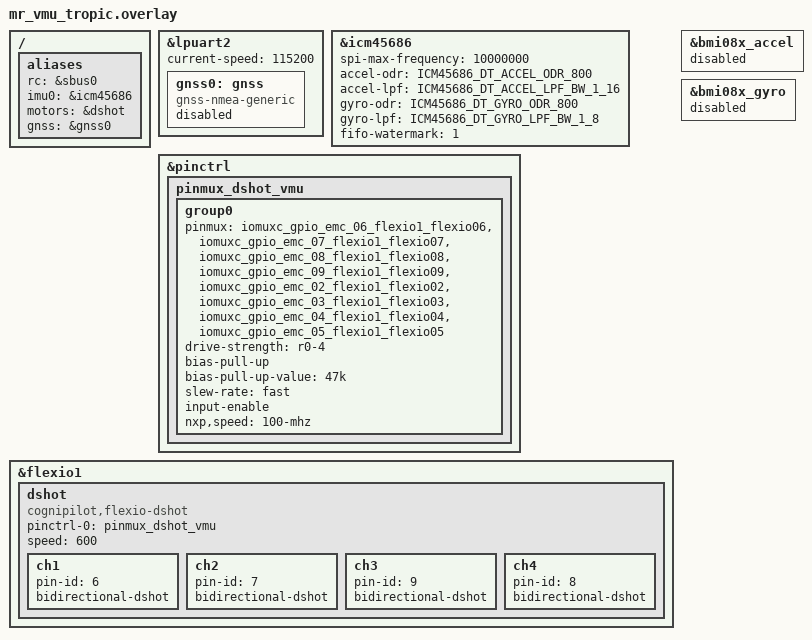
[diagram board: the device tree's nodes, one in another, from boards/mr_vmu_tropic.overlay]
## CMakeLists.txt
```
cmake_minimum_required(VERSION 3.20.0)

list(APPEND DTS_ROOT ${CMAKE_CURRENT_SOURCE_DIR})

get_filename_component(WORKSPACE_ROOT ${CMAKE_CURRENT_SOURCE_DIR} DIRECTORY)
set(ZEPHYR_MODULES
  ${WORKSPACE_ROOT}/modules/hal/cmsis_6
  ${WORKSPACE_ROOT}/modules/hal/nxp
  ${WORKSPACE_ROOT}/modules/lib/zephyr_boards
)

find_package(Zephyr REQUIRED HINTS $ENV{ZEPHYR_BASE})
project(cerebri2 LANGUAGES C)

set(CEREBRI2_FLATBUFFER_SCHEMA_DIR
  ${WORKSPACE_ROOT}/modules/lib/synapse_msgs_fbs/fbs/cerebri2
)
set(CEREBRI2_FLATBUFFER_SCHEMA
  ${CEREBRI2_FLATBUFFER_SCHEMA_DIR}/cerebri2_topics.fbs
)
set(CEREBRI2_FLATBUFFER_LOG_SCHEMA
  ${CEREBRI2_FLATBUFFER_SCHEMA_DIR}/cerebri2_log.fbs
)
set(CEREBRI2_FLATBUFFER_SIL_SCHEMA
  ${CEREBRI2_FLATBUFFER_SCHEMA_DIR}/cerebri2_sil.fbs
)
set(CEREBRI2_FLATBUFFER_GENERATED_DIR
  ${CMAKE_CURRENT_BINARY_DIR}/generated/flatbuffers
)
set(CEREBRI2_FLATBUFFER_STAMP
  ${CEREBRI2_FLATBUFFER_GENERATED_DIR}/.flatcc.stamp
)
set(CEREBRI2_FLATBUFFER_BFBS_STAMP
  ${CEREBRI2_FLATBUFFER_GENERATED_DIR}/.bfbs.stamp
)
set(CEREBRI2_FLATBUFFER_STAGE_STAMP
  ${CEREBRI2_FLATBUFFER_GENERATED_DIR}/.schema-copy.stamp
)
option(CEREBRI2_FLATBUFFER_CODEGEN
  "Generate FlatBuffer C headers and binary schemas into the build tree when flatcc is available"
  ON
)

find_program(CEREBRI2_FLATCC_EXECUTABLE NAMES flatcc)

if(NOT EXISTS ${CEREBRI2_FLATBUFFER_SCHEMA})
  message(FATAL_ERROR
    "Missing FlatBuffer topic schema: ${CEREBRI2_FLATBUFFER_SCHEMA}. "
    "Run west update to fetch modules/lib/synapse_msgs_fbs."
  )
endif()

if(NOT EXISTS ${CEREBRI2_FLATBUFFER_LOG_SCHEMA})
  message(FATAL_ERROR
    "Missing FlatBuffer log schema: ${CEREBRI2_FLATBUFFER_LOG_SCHEMA}. "
    "Run west update to fetch modules/lib/synapse_msgs_fbs."
  )
endif()

if(NOT EXISTS ${CEREBRI2_FLATBUFFER_SIL_SCHEMA})
  message(FATAL_ERROR
    "Missing FlatBuffer SITL schema: ${CEREBRI2_FLATBUFFER_SIL_SCHEMA}. "
    "Run west update to fetch modules/lib/synapse_msgs_fbs."
  )
endif()

if(CEREBRI2_FLATBUFFER_CODEGEN AND CEREBRI2_FLATCC_EXECUTABLE)
  add_custom_command(
    OUTPUT ${CEREBRI2_FLATBUFFER_STAGE_STAMP}
    COMMAND ${CMAKE_COMMAND} -E make_directory ${CEREBRI2_FLATBUFFER_GENERATED_DIR}
    COMMAND ${CMAKE_COMMAND} -E copy_if_different
            ${CEREBRI2_FLATBUFFER_SCHEMA}
            ${CEREBRI2_FLATBUFFER_GENERATED_DIR}/cerebri2_topics.fbs
    COMMAND ${CMAKE_COMMAND} -E copy_if_different
            ${CEREBRI2_FLATBUFFER_LOG_SCHEMA}
            ${CEREBRI2_FLATBUFFER_GENERATED_DIR}/cerebri2_log.fbs
    COMMAND ${CMAKE_COMMAND} -E copy_if_different
            ${CEREBRI2_FLATBUFFER_SIL_SCHEMA}
            ${CEREBRI2_FLATBUFFER_GENERATED_DIR}/cerebri2_sil.fbs
    COMMAND ${CMAKE_COMMAND} -E touch ${CEREBRI2_FLATBUFFER_STAGE_STAMP}
    DEPENDS
      ${CEREBRI2_FLATBUFFER_SCHEMA}
      ${CEREBRI2_FLATBUFFER_LOG_SCHEMA}
      ${CEREBRI2_FLATBUFFER_SIL_SCHEMA}
    COMMENT "Staging FlatBuffer schemas into ${CEREBRI2_FLATBUFFER_GENERATED_DIR}"
    VERBATIM
  )

  add_custom_command(
    OUTPUT ${CEREBRI2_FLATBUFFER_STAMP}
    COMMAND ${CEREBRI2_FLATCC_EXECUTABLE}
            -a
            -I${CEREBRI2_FLATBUFFER_SCHEMA_DIR}
            -o${CEREBRI2_FLATBUFFER_GENERATED_DIR}
            ${CEREBRI2_FLATBUFFER_SCHEMA}
    COMMAND ${CEREBRI2_FLATCC_EXECUTABLE}
            -a
            -I${CEREBRI2_FLATBUFFER_SCHEMA_DIR}
            -o${CEREBRI2_FLATBUFFER_GENERATED_DIR}
            ${CEREBRI2_FLATBUFFER_LOG_SCHEMA}
    COMMAND ${CEREBRI2_FLATCC_EXECUTABLE}
            -a
            -I${CEREBRI2_FLATBUFFER_SCHEMA_DIR}
            -o${CEREBRI2_FLATBUFFER_GENERATED_DIR}
            ${CEREBRI2_FLATBUFFER_SIL_SCHEMA}
    COMMAND ${CMAKE_COMMAND} -E touch ${CEREBRI2_FLATBUFFER_STAMP}
    DEPENDS
      ${CEREBRI2_FLATBUFFER_STAGE_STAMP}
      ${CEREBRI2_FLATBUFFER_SCHEMA}
      ${CEREBRI2_FLATBUFFER_LOG_SCHEMA}
      ${CEREBRI2_FLATBUFFER_SIL_SCHEMA}
    COMMENT "Generating FlatBuffer headers into ${CEREBRI2_FLATBUFFER_GENERATED_DIR}"
    VERBATIM
  )

  add_custom_target(cerebri2_flatbuffer_codegen DEPENDS ${CEREBRI2_FLATBUFFER_STAMP})
  add_custom_command(
    OUTPUT ${CEREBRI2_FLATBUFFER_BFBS_STAMP}
    COMMAND ${CMAKE_COMMAND} -E make_directory ${CEREBRI2_FLATBUFFER_GENERATED_DIR}
    COMMAND ${CMAKE_COMMAND} -E copy_if_different
            ${CEREBRI2_FLATBUFFER_SCHEMA}
            ${CEREBRI2_FLATBUFFER_GENERATED_DIR}/cerebri2_topics.fbs
    COMMAND ${CMAKE_COMMAND} -E copy_if_different
            ${CEREBRI2_FLATBUFFER_LOG_SCHEMA}
            ${CEREBRI2_FLATBUFFER_GENERATED_DIR}/cerebri2_log.fbs
    COMMAND ${CEREBRI2_FLATCC_EXECUTABLE}
            --schema
            -I${CEREBRI2_FLATBUFFER_SCHEMA_DIR}
            -o${CEREBRI2_FLATBUFFER_GENERATED_DIR}
            ${CEREBRI2_FLATBUFFER_SCHEMA}
    COMMAND ${CEREBRI2_FLATCC_EXECUTABLE}
            --schema
            -I${CEREBRI2_FLATBUFFER_SCHEMA_DIR}
            -o${CEREBRI2_FLATBUFFER_GENERATED_DIR}
            ${CEREBRI2_FLATBUFFER_LOG_SCHEMA}
    COMMAND ${CEREBRI2_FLATCC_EXECUTABLE}
            --schema
            -I${CEREBRI2_FLATBUFFER_SCHEMA_DIR}
            -o${CEREBRI2_FLATBUFFER_GENERATED_DIR}
            ${CEREBRI2_FLATBUFFER_SIL_SCHEMA}
    COMMAND ${CMAKE_COMMAND} -E touch ${CEREBRI2_FLATBUFFER_BFBS_STAMP}
    DEPENDS
      ${CEREBRI2_FLATBUFFER_STAGE_STAMP}
      ${CEREBRI2_FLATBUFFER_SCHEMA}
      ${CEREBRI2_FLATBUFFER_LOG_SCHEMA}
      ${CEREBRI2_FLATBUFFER_SIL_SCHEMA}
    COMMENT "Generating FlatBuffer binary schemas into ${CEREBRI2_FLATBUFFER_GENERATED_DIR}"
    VERBATIM
  )

  add_custom_target(cerebri2_flatbuffer_schema_codegen
    DEPENDS ${CEREBRI2_FLATBUFFER_BFBS_STAMP}
  )
elseif(CEREBRI2_FLATBUFFER_CODEGEN)
  message(STATUS
    "flatcc not found; skipping FlatBuffer code generation and using local topic codec only"
  )
endif()

target_sources(app PRIVATE
  src/main.c
  src/rc_input.c
  src/topic_flatbuffer.c
  src/topic_shell.c
  src/PIDAxis.c
  drivers/nxp_flexio_dshot.c
  drivers/nxp_flexio_dshot_api.c
  src/rdd2.c
)

if(CONFIG_CEREBRI2_DSHOT)
  target_sources(app PRIVATE drivers/nxp_flexio_dshot.c)
endif()

if(CONFIG_CEREBRI2_SITL)
  target_sources(app PRIVATE
    src/sitl_flatbuffer.c
    drivers/sitl_dshot.c
    drivers/sitl_imu.c
    drivers/sitl_rc.c
    drivers/sitl_udp_coordinator.c
  )
endif()

if(TARGET cerebri2_flatbuffer_codegen)
  add_dependencies(app cerebri2_flatbuffer_codegen)
endif()

if(TARGET cerebri2_flatbuffer_schema_codegen)
  add_dependencies(app cerebri2_flatbuffer_schema_codegen)
endif()

target_include_directories(app PRIVATE
  include
  src
  ${CEREBRI2_FLATBUFFER_GENERATED_DIR}
  ${ZEPHYR_BASE}/../modules/hal/nxp/mcux/mcux-sdk-ng/drivers/flexio
)

# Automatically takes modelica model and generates it into C code
# Will be uncommented once rumoca is updated with new embedded-c backend
# And updated

#[[
if(TARGET cerebri_flatbuffer_schema_codegen)
  add_dependencies(app cerebri2_flatbuffer_schema_codegen)
endif()

target_include_directories(app PRIVATE
  include
  src
  ${CEREBRI2_FLATBUFFER_GENERATED_DIR}
  ${ZEPHYR_BASE}/../modules/hal/nxp/mcux/mcux-sdk-ng/drivers/flexio
)

# RUMOCA CODE GENERATION
set(RUMOCA_PATH ${WORKSPACE_ROOT}/modules/lib/rumoca)
set(RUMOCA_GENERATED_DIR ${CMAKE_CURRENT_BINARY_DIR}/generated/rumoca)
set(RUMOCA_STAMP ${RUMOCA_GENERATED_DIR}/.rumoca.stamp)

option(CEREBRI2_RUMOCA_CODEGEN
  "Generate rumoca embedded C"
  ON
)

find_program(CEREBRI2_RUMOCA_EXECUTABLE NAMES rumoca)

if (CEREBRI2_RUMOCA_CODEGEN AND CEREBRI2_RUMOCA_EXECUTABLE AND EXISTS ${RUMOCA_PATH}/models/Adder.mo)
  add_custom_command(
    OUTPUT ${RUMOCA_STAMP}
    COMMAND ${CMAKE_COMMAND} -E make_directory ${RUMOCA_GENERATED_DIR}
    COMMAND ${CEREBRI2_RUMOCA_EXECUTABLE} compile -b embedded-c -m Adder ${RUMOCA_PATH}/models/Adder.mo > ${RUMOCA_GENERATED_DIR}/adder.h
    COMMAND ${CMAKE_COMMAND} -E touch ${RUMOCA_STAMP}
    DEPENDS ${RUMOCA_PATH}/models/Adder.mo
    COMMENT "Generating rumoca embedded C code into ${RUMOCA_GENERATED_DIR}"
    VERBATIM
  )

  add_custom_target(cerebri2_rumoca_codegen DEPENDS ${RUMOCA_STAMP})

  if(TARGET cerebri2_rumoca_codegen)
    add_dependencies(app cerebri2_rumoca_codegen)
  endif()

elseif(CEREBRI2_RUMOCA_CODEGEN)
  message(STATUS
    "rumoca not found or Adder.mo missing; skipping rumoca code generation"
  )
endif()

target_include_directories(app PRIVATE
  ${RUMOCA_GENERATED_DIR}
)
]]
```

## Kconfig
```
source "Kconfig.zephyr"

menu "cerebri"

rsource "subsys/Kconfig"
rsource "drivers/Kconfig"

endmenu
```

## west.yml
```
# Copyright (c) 2023 CogniPilot Foundation
# SPDX-License-Identifier: Apache-2.0

manifest:

  group-filter:
    - +optional

  self:
    west-commands: scripts/west-commands.yml

  remotes:
    - name: zephyrproject-rtos
      url-base: https://github.com/zephyrproject-rtos
    - name: cognipilot
      url-base: https://github.com/CogniPilot

  projects:
    - name: zephyr
      remote: cognipilot
      west-commands: scripts/west-commands.yml
      revision: fd02d713535e8e683ec0e34fb942a08fe955878d # main-with-patches 07/06/26
      import:
        - name-allowlist:
          - nanopb
          - mbedtls
          - hal_nxp
          - cmsis
          - cmsis-dsp
          - cmsis_6
          - fatfs
          - open-amp
          - libmetal
          - segger
    - name: zros
      remote: cognipilot
      revision: 843348bca3a15e914914b90057369b9616302e20 # main 10/27/25
      path: modules/lib/zros
    - name: cyecca
      remote: cognipilot
      revision: 64d1f0dc5127d85765909f0c3525cc38305dac19 # main 11/17/25
      path: modules/lib/cyecca
    - name: synapse_pb
      remote: cognipilot
      revision: f038dd178faac0481033e5e4c757e31777c1b0be # main 11/10/25
      path: modules/lib/synapse_pb
    - name: hal_nxp
      remote: cognipilot
      revision: cf8f1631e862528ee044850bcc70273975b90771 # master 10/27/25
      path: modules/hal/nxp
    - name: zros_drivers
      remote: cognipilot
      revision: 61dba155d8f5f8e82419ca8c8901a47dbd00b480 # main 01/07/26
      path: modules/lib/zros_drivers
    - name: zephyr_boards
      remote: cognipilot
      revision: 33ee8e3c572ca53ea048d3ea62cc0c5dcd0895d6 # main 07/06/26
      path: modules/lib/zephyr_boards
```

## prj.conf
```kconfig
CONFIG_MAIN_STACK_SIZE=6144
CONFIG_MAIN_THREAD_PRIORITY=2
CONFIG_SYSTEM_WORKQUEUE_STACK_SIZE=2048
CONFIG_THREAD_NAME=y

CONFIG_ASSERT=y
CONFIG_FPU=y

CONFIG_LOG=y
CONFIG_LOG_MODE_IMMEDIATE=y
CONFIG_LOG_DEFAULT_LEVEL=2
CONFIG_LOG_CMDS=y
CONFIG_LOG_BACKEND_UART=n
CONFIG_LOG_PRINTK=n

CONFIG_CONSOLE=y
CONFIG_SERIAL=y
CONFIG_UART_ASYNC_API=y
CONFIG_UART_INTERRUPT_DRIVEN=y

CONFIG_SHELL=y
CONFIG_SHELL_BACKEND_SERIAL=y
CONFIG_SHELL_LOG_BACKEND=y
CONFIG_SHELL_PROMPT_UART="cerebri2:~$ "
CONFIG_SHELL_STACK_SIZE=4096
CONFIG_DEVICE_SHELL=y
CONFIG_KERNEL_SHELL=y
```

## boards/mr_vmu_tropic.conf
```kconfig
CONFIG_INPUT=y
CONFIG_INPUT_MODE_SYNCHRONOUS=y
CONFIG_INPUT_SHELL=y
CONFIG_INPUT_EVENT_DUMP=y
CONFIG_INPUT_CRSF=y
CONFIG_INPUT_CRSF_SEND_SYNC=y
CONFIG_INPUT_CRSF_REPORT_FILTER=1
CONFIG_INPUT_CRSF_THREAD_PRIORITY=1
CONFIG_INPUT_CRSF_THREAD_STACK_SIZE=2048
CONFIG_INPUT_CRSF_USE_DTCM_FOR_DMA_BUFFER=y

CONFIG_SENSOR=y
CONFIG_SENSOR_SHELL=y
CONFIG_ICM45686_STREAM=y
CONFIG_PINCTRL=y
CONFIG_CLOCK_CONTROL=y
CONFIG_DMA=y
CONFIG_SPI_NXP_LPSPI_DMA=n
CONFIG_GNSS=y
```

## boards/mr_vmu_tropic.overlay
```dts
/* SPDX-License-Identifier: Apache-2.0 */

#include <zephyr/dt-bindings/sensor/icm45686.h>

/ {
	aliases {
		rc = &sbus0;
		imu0 = &icm45686;
		motors = &dshot;
		gnss = &gnss0;
	};
};

&lpuart2 {
	status = "okay";
	current-speed = <115200>;

	gnss0: gnss {
		status = "disabled";
		compatible = "gnss-nmea-generic";
	};
};

&icm45686 {
	spi-max-frequency = <10000000>;
	/*
	 * Pace the flight loop directly from the IMU FIFO watermark at 800 Hz.
	 * Keep the filter settings conservative enough to cut motor vibration,
	 * but leave the SPI DMA channels intact so the FIFO read can stay off
	 * the CPU hot path.
	 */
	accel-odr = <ICM45686_DT_ACCEL_ODR_800>;
	accel-lpf = <ICM45686_DT_ACCEL_LPF_BW_1_16>;
	gyro-odr = <ICM45686_DT_GYRO_ODR_800>;
	gyro-lpf = <ICM45686_DT_GYRO_LPF_BW_1_8>;
	fifo-watermark = <1>;
};

&pinctrl {
	pinmux_dshot_vmu: pinmux_dshot_vmu {
		group0 {
			pinmux = <&iomuxc_gpio_emc_06_flexio1_flexio06>,
				 <&iomuxc_gpio_emc_07_flexio1_flexio07>,
				 <&iomuxc_gpio_emc_08_flexio1_flexio08>,
				 <&iomuxc_gpio_emc_09_flexio1_flexio09>,
				 <&iomuxc_gpio_emc_02_flexio1_flexio02>,
				 <&iomuxc_gpio_emc_03_flexio1_flexio03>,
				 <&iomuxc_gpio_emc_04_flexio1_flexio04>,
				 <&iomuxc_gpio_emc_05_flexio1_flexio05>;
			drive-strength = "r0-4";
			bias-pull-up;
			bias-pull-up-value = "47k";
			slew-rate = "fast";
			input-enable;
			nxp,speed = "100-mhz";
		};
	};
};

&flexio1 {
	status = "okay";

	dshot: dshot {
		compatible = "cognipilot,flexio-dshot";
		pinctrl-0 = <&pinmux_dshot_vmu>;
		pinctrl-names = "default";
		status = "okay";
		speed = <600>;

		ch1 {
			pin-id = <6>;
			bidirectional-dshot;
		};

		ch2 {
			pin-id = <7>;
			bidirectional-dshot;
		};

		ch3 {
			pin-id = <9>;
			bidirectional-dshot;
		};

		ch4 {
			pin-id = <8>;
			bidirectional-dshot;
		};
	};
};

&bmi08x_accel {
	status = "disabled";
};

&bmi08x_gyro {
	status = "disabled";
};
```

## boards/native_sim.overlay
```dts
/* SPDX-License-Identifier: Apache-2.0 */

/ {
	aliases {
		rc = &sitl_rc0;
		imu0 = &sitl_imu0;
		motors = &sitl_dshot0;
	};

	sitl_rc0: sitl_rc {
		compatible = "cognipilot,sitl-rc";
		status = "okay";
	};

	sitl_imu0: sitl_imu {
		compatible = "cognipilot,sitl-imu";
		status = "okay";
	};

	sitl_dshot0: sitl_dshot {
		compatible = "cognipilot,sitl-dshot";
		status = "okay";
		channel-count = <4>;
	};
};
```

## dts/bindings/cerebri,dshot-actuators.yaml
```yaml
# Copyright CogniPilot Foundation 2024
# SPDX-License-Identifier: Apache-2.0

description: DSHOT actuators parent node

  A generic binding for DSHOT actuators. Note that this binding
  has no vendor prefix, as it does not target a specific device or vendor.

compatible: "cerebri,dshot-actuators"

properties:
  rate:
    type: int
    default: 200
    description: |
      Update rate of the dshot signal in Hz

  disarm-timeout-ms:
    type: int
    default: 20
    description: |
      Inactivity timeout to disarm the DShot actuators, which is: no actuator
      update is received within this time.

child-binding:
  description: DSHOT actuators node
  properties:
    label:
      type: string
      description : user label

    center:
      required: true
      type: int
      description: Center dshot defaults to signal in ms to send (maps 0 input to dshot)

    scale:
      required: true
      type: int
      description: The scale in dshot per unit of input

    scale-div:
      default: 1
      type: int
      description: A divisor for the scale

    input-index:
      required: true
      type: int
      description: Index of actuator field specified by actuator input-type.

    input-type:
      required: true
      type: string
      description: What type of input singal to actuators
      enum:
        - "normalized"
        - "velocity"
```

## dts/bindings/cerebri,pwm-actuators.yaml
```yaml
# Copyright CogniPilot Foundation 2024
# SPDX-License-Identifier: Apache-2.0

description: PWM actuators parent node

  A generic binding for PWM actuators. Note that this binding
  has no vendor prefix, as it does not target a specific device or vendor.

compatible: "cerebri,pwm-actuators"

child-binding:
  description: PWM actuators node
  properties:
    label:
      type: string
      description : user label

    pwms:
      required: true
      type: phandle-array
      description: Reference to a PWM instance.

    disarmed:
      default: 1000
      type: int
      description: pwm defaults to signal in ms to send when disarmed

    min:
      default: 1100
      type: int
      description: Minimum pwm defaults to signal in ms to send

    center:
      required: true
      type: int
      description: Center pwm defaults to signal in ms to send (maps 0 input to pwm)

    scale:
      required: true
      type: int
      description: The scale in pwm per unit of input

    scale-div:
      default: 1
      type: int
      description: A divisor for the scale

    max:
      default: 1900
      type: int
      description: Maximum pwm defaults to signal in ms to send

    use-nano-seconds:
      type: boolean
      description: Use nanoseconds for pwm signal

    input-index:
      required: true
      type: int
      description: Index of actuator field specified by actuator input-type.

    input-type:
      required: true
      type: string
      description: What type of input singal to actuators
      enum:
        - "normalized"
        - "position"
        - "velocity"
```

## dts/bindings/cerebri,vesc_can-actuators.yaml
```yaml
# Copyright CogniPilot Foundation 2024
# SPDX-License-Identifier: Apache-2.0

description: VESC_CAN actuators parent node

  A generic binding for VESC_CAN actuators. Note that this binding
  has no vendor prefix, as it does not target a specific device or vendor.

compatible: "cerebri,vesc_can-actuators"

properties:
  device:
    required: true
    type: phandle
    description: Reference to a VESC_CAN instance.

  fd:
    type: boolean
    description: enable CAN FD mode

  pub-wheel-odometry:
    type: boolean
    description: Publishes wheel odometry on the average of all wheels

  status-rate:
    required: true
    type: int
    description: vesc can status publication rate in Hz. If status-rate <0> disables.

child-binding:
  description: VESC_CAN actuators node
  properties:

    vesc-id:
      required: true
      type: int
      description: vesc can bus id

    pole-pair:
      required: true
      type: int
      description: number of pole pairs

    input-index:
      required: true
      type: int
      description: Index of actuator field specified by actuator input-type.

    input-type:
      required: true
      type: string
      description: What type of input singal to actuators
      enum:
        - "normalized"
        - "position"
        - "velocity"
```

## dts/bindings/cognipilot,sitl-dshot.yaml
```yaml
# SPDX-License-Identifier: Apache-2.0

description: Cerebri native_sim DSHOT output device

compatible: "cognipilot,sitl-dshot"

include: sensor-device.yaml

properties:
  channel-count:
    type: int
    required: true
    description: Number of simulated motor output channels.
```

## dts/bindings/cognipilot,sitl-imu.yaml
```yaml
# SPDX-License-Identifier: Apache-2.0

description: Cerebri native_sim IMU sensor device

compatible: "cognipilot,sitl-imu"

include: sensor-device.yaml
```

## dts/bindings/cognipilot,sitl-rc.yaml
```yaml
# SPDX-License-Identifier: Apache-2.0

description: Cerebri native_sim RC input device

compatible: "cognipilot,sitl-rc"

include: base.yaml
```

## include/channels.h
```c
#ifndef DC9A7AA6_4867_45B4_B139_1F16E724ECC6
#define DC9A7AA6_4867_45B4_B139_1F16E724ECC6

#include <zephyr/zbus/zbus.h>
#include "messages.h"

// sensor measurements
ZBUS_CHAN_DECLARE(chan_accelerometer);
ZBUS_CHAN_DECLARE(chan_gyroscope);
ZBUS_CHAN_DECLARE(chan_magnetometer);
ZBUS_CHAN_DECLARE(chan_altimeter);
ZBUS_CHAN_DECLARE(chan_navsat);
ZBUS_CHAN_DECLARE(chan_external_odometry);

// commands
ZBUS_CHAN_DECLARE(chan_rc_input);
ZBUS_CHAN_DECLARE(chan_trajectory);

// estimation
ZBUS_CHAN_DECLARE(chan_estimator_odometry);

// control
ZBUS_CHAN_DECLARE(chan_actuators);

#endif /* DC9A7AA6_4867_45B4_B139_1F16E724ECC6 */
```

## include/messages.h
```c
#ifndef D00B381E_08D8_47AC_B779_57B422AF3850
#define D00B381E_08D8_47AC_B779_57B422AF3850

enum actuator_type_t{
    ACTUATOR_TYPE_UNDEFINED = 0,
    ACTUATOR_TYPE_ANGULAR_POSITION,
    ACTUATOR_TYPE_ANGULAR_VELOCITY,
    ACTUATOR_TYPE_LINEAR_POSITION,
    ACTUATOR_TYPE_LINEAR_VELOCITY,
    ACTUATOR_TYPE_FORCE,
    ACTUATOR_TYPE_TORQUE,
    ACTUATOR_TYPE_END
};
struct msg_actuators_t {
    uint64_t uptime_nsec;
    double actuator0_value;
    uint8_t actuator0_type;
    double actuator1_value;
    uint8_t actuator1_type;
    double actuator2_value;
    uint8_t actuator2_type;
    double actuator3_value;
    uint8_t actuator3_type;
    double actuator4_value;
    uint8_t actuator4_type;
    double actuator5_value;
    uint8_t actuator5_type;
    double actuator6_value;
    uint8_t actuator6_type;
    double actuator7_value;
    uint8_t actuator7_type;
};

struct msg_accelerometer_t {
    uint64_t uptime_nsec;
    double x;
    double y;
    double z;
};

struct msg_gyroscope_t {
    uint64_t uptime_nsec;
    double x;
    double y;
    double z;
};

struct msg_magnetometer_t {
    uint64_t uptime_nsec;
    double x;
    double y;
    double z;
};

struct msg_altimeter_t {
    uint64_t uptime_nsec;
    double position;
    double reference;
    double velocity;
};

struct msg_navsat_t {
    uint64_t uptime_nsec;
    double latitude_deg;
    double longitude_deg;
    double altitude;
    double velocity_east;
    double velocity_north;
    double velocity_up;
};

struct msg_trajectory_t {
    uint64_t uptime_nsec;
    uint16_t sequence;
    uint64_t time_start;
    uint64_t time_stop;
    double x[8];
    double y[8];
    double z[8];
    double yaw[8];
};

struct msg_rc_input_t {
    uint64_t uptime_nsec;
    double roll;
    double pitch;
    double yaw;
    double thrust;
    int mode;
    bool armed;
};

struct msg_odometry_t {
    uint64_t uptime_nsec;
    double x;
    double y;
    double z;
    double qx;
    double qy;
    double qz;
    double qw;
    double vx;
    double vy;
    double vz;
    double wx;
    double wy;
    double wz;
    double pose_cov[36];
    double twist_cov[36];
    char child_frame_id[10];
    char parent_frame_id[10];
};



#endif /* D00B381E_08D8_47AC_B779_57B422AF3850 */
```

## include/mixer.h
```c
#ifndef D00B213E_08D8_47AC_B779_57B422AF3850
#define D00B213E_08D8_47AC_B779_57B422AF3850

struct msg_actuators_t mixer(const struct msg_rc_input_t * msg_rc_input);

#endif /* D00B213E_08D8_47AC_B779_57B422AF3850 */
```

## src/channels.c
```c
#include "channels.h"

ZBUS_CHAN_DEFINE(chan_actuators, // Name
    struct msg_actuators_t, // Message type
    NULL, // Validator
    NULL, // User Data
    ZBUS_OBSERVERS(listener_sim_actuators), // observers
    ZBUS_MSG_INIT(0) // Initial value {0}
);

ZBUS_CHAN_DEFINE(chan_accelerometer, // Name
    struct msg_accelerometer_t, // Message type
    NULL, // Validator
    NULL, // User Data
    ZBUS_OBSERVERS(listener_estimator), // observers
    ZBUS_MSG_INIT(0) // Initial value {0}
);

ZBUS_CHAN_DEFINE(chan_gyroscope, // Name
    struct msg_gyroscope_t, // Message type
    NULL, // Validator
    NULL, // User Data
    ZBUS_OBSERVERS(listener_estimator, listener_controller), // observers
    ZBUS_MSG_INIT(0) // Initial value {0}
);

ZBUS_CHAN_DEFINE(chan_magnetometer, // Name
    struct msg_magnetometer_t, // Message type
    NULL, // Validator
    NULL, // User Data
    ZBUS_OBSERVERS(listener_estimator), // observers
    ZBUS_MSG_INIT(0) // Initial value {0}
);

ZBUS_CHAN_DEFINE(chan_altimeter, // Name
    struct msg_altimeter_t, // Message type
    NULL, // Validator
    NULL, // User Data
    ZBUS_OBSERVERS(listener_estimator), // observers
    ZBUS_MSG_INIT(0) // Initial value {0}
);

ZBUS_CHAN_DEFINE(chan_navsat, // Name
    struct msg_navsat_t, // Message type
    NULL, // Validator
    NULL, // User Data
    ZBUS_OBSERVERS(listener_estimator), // observers
    ZBUS_MSG_INIT(0) // Initial value {0}
);

ZBUS_CHAN_DEFINE(chan_waypoint, // Name
    struct msg_waypoint_t, // Message type
    NULL, // Validator
    NULL, // User Data
    ZBUS_OBSERVERS(), // observers
    ZBUS_MSG_INIT(0) // Initial value {0}
);

ZBUS_CHAN_DEFINE(chan_rc_input, // Name
    struct msg_rc_input_t, // Message type
    NULL, // Validator
    NULL, // User Data
    ZBUS_OBSERVERS(listener_controller), // observers
    ZBUS_MSG_INIT(0) // Initial value {0}
);
```

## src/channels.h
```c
#ifndef DC9A7AA6_4867_45B4_B139_1F16E724ECC6
#define DC9A7AA6_4867_45B4_B139_1F16E724ECC6

#include <zephyr/zbus/zbus.h>
#include "messages.h"

ZBUS_CHAN_DECLARE(chan_actuators);
ZBUS_CHAN_DECLARE(chan_accelerometer);
ZBUS_CHAN_DECLARE(chan_gyroscope);
ZBUS_CHAN_DECLARE(chan_magnetometer);
ZBUS_CHAN_DECLARE(chan_altimeter);
ZBUS_CHAN_DECLARE(chan_navsat);
ZBUS_CHAN_DECLARE(chan_waypoint);
ZBUS_CHAN_DECLARE(chan_rc_input);

#endif /* DC9A7AA6_4867_45B4_B139_1F16E724ECC6 */
```

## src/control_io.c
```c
/*
 * SPDX-License-Identifier: Apache-2.0
 */

#include "control_io.h"

#include "imu_stream.h"
#include "rc_input.h"

#include <errno.h>

#include <zephyr/device.h>
#include <zephyr/drivers/misc/nxp_flexio_dshot/nxp_flexio_dshot.h>
#include <zephyr/logging/log.h>

LOG_MODULE_DECLARE(cerebri, LOG_LEVEL_INF);

#define RC_NODE    DT_ALIAS(rc)
#define IMU_NODE   DT_ALIAS(imu0)
#define DSHOT_NODE DT_ALIAS(motors)
#define GNSS_NODE  DT_ALIAS(gnss)

static bool ready_or_log(const struct device *dev, const char *name)
{
	if (!device_is_ready(dev)) {
		LOG_ERR("%s not ready", name);
		return false;
	}

	return true;
}

int cerebri_control_io_init(void)
{
	const struct device *const rc_dev = DEVICE_DT_GET(RC_NODE);
	const struct device *const imu_dev = DEVICE_DT_GET(IMU_NODE);
	const struct device *const dshot_dev = DEVICE_DT_GET(DSHOT_NODE);
	const struct device *const gnss_dev = DEVICE_DT_GET_OR_NULL(GNSS_NODE);

	cerebri_rc_input_init();

	if (!ready_or_log(dshot_dev, "dshot")) {
		return -ENODEV;
	}

	ready_or_log(rc_dev, "rc");
	ready_or_log(imu_dev, "imu");

	if (gnss_dev != NULL && device_is_ready(gnss_dev)) {
		LOG_INF("gnss path ready");
	}

	if (nxp_flexio_dshot_channel_count(dshot_dev) != 4U) {
		LOG_ERR("expected 4 dshot channels");
		return -EINVAL;
	}

	return cerebri_imu_stream_init();
}

void cerebri_control_input_wait(cerebri_topic_Vec3f_t *gyro,
				cerebri_topic_Vec3f_t *accel,
				cerebri_topic_RcChannels16_t *rc,
				cerebri_topic_ControlStatus_t *status,
				float *dt)
{
	bool rc_valid;

	status->imu_ok = cerebri_imu_stream_wait_next(gyro, accel, dt);
	status->rc_link_quality = cerebri_rc_input_link_quality_get(DEVICE_DT_GET(RC_NODE));
	cerebri_rc_input_latest_get(rc, &status->rc_stamp_ms, &rc_valid);
	status->rc_valid = rc_valid;
}
```

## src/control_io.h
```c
#ifndef CEREBRI_CONTROL_IO_H_
#define CEREBRI_CONTROL_IO_H_

#include "topic_flatbuffer.h"

int cerebri_control_io_init(void);
void cerebri_control_input_wait(cerebri_topic_Vec3f_t *gyro,
				cerebri_topic_Vec3f_t *accel,
				cerebri_topic_RcChannels16_t *rc,
				cerebri_topic_ControlStatus_t *status,
				float *dt);

#endif
```

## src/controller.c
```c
#include <zephyr/kernel.h>
#include <math.h>

#include "channels.h"
#include <stdio.h>

float gx = 0;
float gy = 0;
float gz = 0;void listener_controller_callback(const struct zbus_channel *chan) {
    
    
    if (chan == &chan_rc_input) {
        const struct msg_rc_input_t *msg_rc_input = (const struct msg_rc_input_t *)zbus_chan_const_msg(chan);
        struct msg_actuators_t actuators_msg;
        double vt = msg_rc_input->thrust;

        double vy = msg_rc_input->yaw;
  
        bool armed = msg_rc_input->armed;

        double mix_thrust = armed ? vt : 0;
        double mix_yaw = armed ? vy : 0;
    
        double scale0 = (0.4 - -0.4) / 2.0;
        double actuator0 = 0*mix_thrust*scale0 + 1*mix_yaw*scale0;
        if(actuator0 > 0.4) {
            actuator0 = 0.4;
        } else if (actuator0 < -0.4) {
            actuator0 = -0.4;
        }
        actuators_msg.actuator0_value = actuator0;
    
        double scale1 = (50 - -50) / 2.0;
        double actuator1 =  1*mix_thrust*scale1 +  0*mix_yaw*scale1;
        if(actuator1 > 50) {
            actuator1 = 50;
        } else if (actuator1 < -50) {
            actuator1 = -50;
        }
        actuators_msg.actuator1_value = actuator1;
    

        zbus_chan_pub(&chan_actuators, &actuators_msg, K_NO_WAIT);

    } else if (chan == &chan_gyroscope) {
        const struct msg_gyroscope_t * msg_gyroscope = (const struct msg_gyroscope_t *)zbus_chan_const_msg(chan);
        gx = msg_gyroscope->x;
        gy = msg_gyroscope->y;
        gz = msg_gyroscope->z;
    }
}
ZBUS_LISTENER_DEFINE(listener_controller, listener_controller_callback);
```

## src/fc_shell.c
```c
/*
 * SPDX-License-Identifier: Apache-2.0
 */

#include "topic_shell.h"

#include <zephyr/kernel.h>
#include <zephyr/shell/shell.h>

static void fc_latest_state(cerebri_topic_Vec3f_t *gyro, cerebri_topic_Vec3f_t *accel,
			    cerebri_topic_RcChannels16_t *rc,
			    cerebri_topic_ControlStatus_t *status,
			    cerebri_topic_RateTriplet_t *rate_desired,
			    cerebri_topic_RateTriplet_t *rate_cmd)
{
	(void)cerebri_topic_flight_state_get(gyro, accel, rc, status, rate_desired, rate_cmd);
}

static int cmd_fc_status(const struct shell *sh, size_t argc, char **argv)
{
	cerebri_topic_Vec3f_t gyro = {0};
	cerebri_topic_Vec3f_t accel = {0};
	cerebri_topic_RcChannels16_t rc = {0};
	cerebri_topic_ControlStatus_t status = {0};
	cerebri_topic_RateTriplet_t rate_desired = {0};
	cerebri_topic_RateTriplet_t rate_cmd = {0};
	int64_t now_ms = k_uptime_get();
	int64_t rc_age_ms;

	ARG_UNUSED(argc);
	ARG_UNUSED(argv);

	fc_latest_state(&gyro, &accel, &rc, &status, &rate_desired, &rate_cmd);
	rc_age_ms = status.rc_valid ? (now_ms - status.rc_stamp_ms) : -1;

	shell_print(sh,
		    "armed=%d imu_ok=%d rc_valid=%d rc_stale=%d arm_switch=%d rc_age_ms=%lld lq=%u throttle_us=%ld",
		    status.armed ? 1 : 0,
		    status.imu_ok ? 1 : 0,
		    status.rc_valid ? 1 : 0,
		    status.rc_stale ? 1 : 0,
		    status.arm_switch ? 1 : 0,
		    (long long)rc_age_ms,
		    (unsigned int)status.rc_link_quality,
		    (long)status.throttle_us);
	shell_print(sh,
		    "rate_desired roll=%0.3f pitch=%0.3f yaw=%0.3f rate_cmd roll=%0.3f pitch=%0.3f yaw=%0.3f",
		    (double)rate_desired.roll,
		    (double)rate_desired.pitch,
		    (double)rate_desired.yaw,
		    (double)rate_cmd.roll,
		    (double)rate_cmd.pitch,
		    (double)rate_cmd.yaw);

	return 0;
}

static int cmd_fc_gyro(const struct shell *sh, size_t argc, char **argv)
{
	cerebri_topic_Vec3f_t gyro = {0};
	cerebri_topic_Vec3f_t accel = {0};
	cerebri_topic_RcChannels16_t rc = {0};
	cerebri_topic_ControlStatus_t status = {0};
	cerebri_topic_RateTriplet_t rate_desired = {0};
	cerebri_topic_RateTriplet_t rate_cmd = {0};

	ARG_UNUSED(argc);
	ARG_UNUSED(argv);

	fc_latest_state(&gyro, &accel, &rc, &status, &rate_desired, &rate_cmd);

	shell_print(sh,
		    "gyro_rad_s x=%0.5f y=%0.5f z=%0.5f",
		    (double)gyro.x,
		    (double)gyro.y,
		    (double)gyro.z);
	shell_print(sh,
		    "accel_m_s2 x=%0.5f y=%0.5f z=%0.5f",
		    (double)accel.x,
		    (double)accel.y,
		    (double)accel.z);

	return 0;
}

static int cmd_fc_rc(const struct shell *sh, size_t argc, char **argv)
{
	cerebri_topic_Vec3f_t gyro = {0};
	cerebri_topic_Vec3f_t accel = {0};
	cerebri_topic_RcChannels16_t rc = {0};
	cerebri_topic_ControlStatus_t status = {0};
	cerebri_topic_RateTriplet_t rate_desired = {0};
	cerebri_topic_RateTriplet_t rate_cmd = {0};

	ARG_UNUSED(argc);
	ARG_UNUSED(argv);

	fc_latest_state(&gyro, &accel, &rc, &status, &rate_desired, &rate_cmd);

	shell_print(sh,
		    "rc us ch0=%ld ch1=%ld ch2=%ld ch3=%ld ch4=%ld ch5=%ld ch6=%ld ch7=%ld",
		    (long)rc.ch0,
		    (long)rc.ch1,
		    (long)rc.ch2,
		    (long)rc.ch3,
		    (long)rc.ch4,
		    (long)rc.ch5,
		    (long)rc.ch6,
		    (long)rc.ch7);

	return 0;
}

SHELL_STATIC_SUBCMD_SET_CREATE(
	sub_fc,
	SHELL_CMD(status, NULL, "show latest flight-control state", cmd_fc_status),
	SHELL_CMD(gyro, NULL, "show latest gyro and accel sample", cmd_fc_gyro),
	SHELL_CMD(rc, NULL, "show latest RC channel sample", cmd_fc_rc),
	SHELL_SUBCMD_SET_END);
SHELL_CMD_REGISTER(fc, &sub_fc, "flight-control debug commands", NULL);
```

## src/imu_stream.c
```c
/*
 * SPDX-License-Identifier: Apache-2.0
 */

#include "imu_stream.h"

#include "rate_control.h"

#include <errno.h>
#include <string.h>

#include <zephyr/device.h>
#include <zephyr/drivers/sensor.h>
#include <zephyr/drivers/sensor_data_types.h>
#include <zephyr/kernel.h>
#include <zephyr/logging/log.h>
#include <zephyr/rtio/rtio.h>

LOG_MODULE_DECLARE(cerebri, LOG_LEVEL_INF);

#define IMU_NODE DT_ALIAS(imu0)
#define CEREBRI_IMU_TIMEOUT_US (4U * CEREBRI_CONTROL_PERIOD_US)
#define CEREBRI_IMU_RTIO_SQ_COUNT 16U
#define CEREBRI_IMU_RTIO_CQ_COUNT 16U
#define CEREBRI_IMU_RTIO_BUF_COUNT 32U
#define CEREBRI_IMU_RTIO_BUF_SIZE 128U

#if DT_NODE_HAS_COMPAT(IMU_NODE, invensense_icm45686) && defined(CONFIG_SENSOR_ASYNC_API) && \
	defined(CONFIG_DSP)
#include <zephyr/dsp/utils.h>
#endif

static void imu_outputs_zero(cerebri_topic_Vec3f_t *gyro, cerebri_topic_Vec3f_t *accel)
{
	*gyro = (cerebri_topic_Vec3f_t){0};
	*accel = (cerebri_topic_Vec3f_t){0};
}

#if DT_NODE_HAS_COMPAT(IMU_NODE, invensense_icm45686) && defined(CONFIG_SENSOR_ASYNC_API) && \
	defined(CONFIG_DSP)

SENSOR_DT_STREAM_IODEV(cerebri_imu_stream_iodev, IMU_NODE,
		       { SENSOR_TRIG_FIFO_WATERMARK, SENSOR_STREAM_DATA_INCLUDE });

/*
 * The ICM45686 stream path is self-sustaining. Give it enough queue and buffer
 * headroom to absorb brief startup stalls without starving the ISR-side RTIO
 * buffer acquisition path.
 */
RTIO_DEFINE_WITH_MEMPOOL(cerebri_imu_rtio,
			 CEREBRI_IMU_RTIO_SQ_COUNT,
			 CEREBRI_IMU_RTIO_CQ_COUNT,
			 CEREBRI_IMU_RTIO_BUF_COUNT,
			 CEREBRI_IMU_RTIO_BUF_SIZE,
			 sizeof(void *));

static const struct device *const g_imu_dev = DEVICE_DT_GET(IMU_NODE);
static const struct sensor_decoder_api *g_imu_decoder;
static struct rtio_sqe *g_imu_stream_handle;
static uint64_t g_last_sample_ns;
static bool g_have_last_sample;

static uint64_t imu_sample_timestamp_ns(const struct sensor_three_axis_data *sample)
{
	return sample->header.base_timestamp_ns + sample->readings[0].timestamp_delta;
}

static float imu_q31_to_float(q31_t value, int8_t shift)
{
	/*
	 * ICM45686 only emits non-negative q31 shifts in Zephyr's decoder.
	 * Use the shared DSP utility rather than maintaining a local conversion.
	 */
	return (float)Z_SHIFT_Q31_TO_F32(value, shift);
}

static void imu_sensor_axes_to_body(const struct sensor_three_axis_data *gyro_sensor,
				    const struct sensor_three_axis_data *accel_sensor,
				    cerebri_topic_Vec3f_t *gyro_out,
				    cerebri_topic_Vec3f_t *accel_out)
{
	const float gyro_x = imu_q31_to_float(gyro_sensor->readings[0].x, gyro_sensor->shift);
	const float gyro_y = imu_q31_to_float(gyro_sensor->readings[0].y, gyro_sensor->shift);
	const float gyro_z = imu_q31_to_float(gyro_sensor->readings[0].z, gyro_sensor->shift);
	const float accel_x = imu_q31_to_float(accel_sensor->readings[0].x, accel_sensor->shift);
	const float accel_y = imu_q31_to_float(accel_sensor->readings[0].y, accel_sensor->shift);
	const float accel_z = imu_q31_to_float(accel_sensor->readings[0].z, accel_sensor->shift);

	/*
	 * Control code consumes IMU data in FRD body axes:
	 * body roll  (F / x) <- sensor gyro y
	 * body pitch (R / y) <- sensor gyro x
	 * body yaw   (D / z) <- -sensor gyro z
	 *
	 * Apply the same axis remap to accel so future attitude-estimator code
	 * sees a consistent body frame.
	 */
	gyro_out->x = gyro_y;
	gyro_out->y = gyro_x;
	gyro_out->z = -gyro_z;

	accel_out->x = accel_y;
	accel_out->y = accel_x;
	accel_out->z = -accel_z;
}

static int imu_decode_latest_three_axis(const uint8_t *buf, struct sensor_chan_spec chan_spec,
					struct sensor_three_axis_data *sample,
					uint64_t *timestamp_ns)
{
	uint16_t frame_count = 0;
	uint32_t fit = 0;
	int rc;

	rc = g_imu_decoder->get_frame_count(buf, chan_spec, &frame_count);
	if (rc != 0 || frame_count == 0U) {
		return rc == 0 ? -ENODATA : rc;
	}

	while (fit < frame_count) {
		rc = g_imu_decoder->decode(buf, chan_spec, &fit, 1, sample);
		if (rc <= 0) {
			return rc == 0 ? -ENODATA : rc;
		}
	}

	*timestamp_ns = imu_sample_timestamp_ns(sample);
	return 0;
}

static bool imu_stream_decode_latest(const uint8_t *buf, cerebri_topic_Vec3f_t *gyro,
				     cerebri_topic_Vec3f_t *accel, uint64_t *sample_ns)
{
	const struct sensor_chan_spec gyro_chan = { SENSOR_CHAN_GYRO_XYZ, 0 };
	const struct sensor_chan_spec accel_chan = { SENSOR_CHAN_ACCEL_XYZ, 0 };
	struct sensor_three_axis_data gyro_sample = {0};
	struct sensor_three_axis_data accel_sample = {0};
	uint64_t gyro_ns = 0;
	uint64_t accel_ns = 0;
	int rc;

	rc = imu_decode_latest_three_axis(buf, gyro_chan, &gyro_sample, &gyro_ns);
	if (rc != 0) {
		return false;
	}

	rc = imu_decode_latest_three_axis(buf, accel_chan, &accel_sample, &accel_ns);
	if (rc != 0) {
		return false;
	}

	imu_sensor_axes_to_body(&gyro_sample, &accel_sample, gyro, accel);
	*sample_ns = (gyro_ns >= accel_ns) ? gyro_ns : accel_ns;
	return true;
}

int cerebri_imu_stream_init(void)
{
	int rc;

	if (!device_is_ready(g_imu_dev)) {
		return -ENODEV;
	}

	rc = sensor_get_decoder(g_imu_dev, &g_imu_decoder);
	if (rc != 0) {
		LOG_ERR("imu decoder unavailable: %d", rc);
		return rc;
	}

	rc = sensor_stream(&cerebri_imu_stream_iodev, &cerebri_imu_rtio, NULL,
			   &g_imu_stream_handle);
	if (rc != 0) {
		LOG_ERR("imu stream start failed: %d", rc);
		return rc;
	}

	g_have_last_sample = false;
	return 0;
}

bool cerebri_imu_stream_wait_next(cerebri_topic_Vec3f_t *gyro,
				  cerebri_topic_Vec3f_t *accel,
				  float *dt)
{
	struct rtio_cqe *cqe;
	uint8_t *buf = NULL;
	uint32_t buf_len = 0;
	uint64_t sample_ns = 0;
	int rc;

	*dt = (float)CEREBRI_CONTROL_PERIOD_US * 1.0e-6f;

	cqe = rtio_cqe_consume_block_timeout(&cerebri_imu_rtio, K_USEC(CEREBRI_IMU_TIMEOUT_US));
	if (cqe == NULL) {
		imu_outputs_zero(gyro, accel);
		return false;
	}

	rc = cqe->result;
	if (rc == 0) {
		rc = rtio_cqe_get_mempool_buffer(&cerebri_imu_rtio, cqe, &buf, &buf_len);
	}
	rtio_cqe_release(&cerebri_imu_rtio, cqe);

	if (rc != 0) {
		imu_outputs_zero(gyro, accel);
		return false;
	}

	if (!imu_stream_decode_latest(buf, gyro, accel, &sample_ns)) {
		rtio_release_buffer(&cerebri_imu_rtio, buf, buf_len);
		imu_outputs_zero(gyro, accel);
		return false;
	}

	rtio_release_buffer(&cerebri_imu_rtio, buf, buf_len);

	if (g_have_last_sample && sample_ns > g_last_sample_ns) {
		*dt = (float)(sample_ns - g_last_sample_ns) * 1.0e-9f;
	}

	g_last_sample_ns = sample_ns;
	g_have_last_sample = true;
	return true;
}

#else

static bool imu_fetch_sync(cerebri_topic_Vec3f_t *gyro_out, cerebri_topic_Vec3f_t *accel_out)
{
	const struct device *const imu_dev = DEVICE_DT_GET(IMU_NODE);
	struct sensor_value gyro[3];
	struct sensor_value accel_values[3];
	float gyro_sensor[3];
	float accel_sensor[3];
	int rc;

	rc = sensor_sample_fetch(imu_dev);
	if (rc != 0) {
		return false;
	}

	rc = sensor_channel_get(imu_dev, SENSOR_CHAN_GYRO_XYZ, gyro);
	if (rc != 0) {
		return false;
	}

	rc = sensor_channel_get(imu_dev, SENSOR_CHAN_ACCEL_XYZ, accel_values);
	if (rc != 0) {
		return false;
	}

	for (size_t i = 0; i < 3; i++) {
		gyro_sensor[i] = sensor_value_to_float(&gyro[i]);
		accel_sensor[i] = sensor_value_to_float(&accel_values[i]);
	}

	gyro_out->x = gyro_sensor[1];
	gyro_out->y = gyro_sensor[0];
	gyro_out->z = -gyro_sensor[2];

	accel_out->x = accel_sensor[1];
	accel_out->y = accel_sensor[0];
	accel_out->z = -accel_sensor[2];

	return true;
}

int cerebri_imu_stream_init(void)
{
	return 0;
}

bool cerebri_imu_stream_wait_next(cerebri_topic_Vec3f_t *gyro,
				  cerebri_topic_Vec3f_t *accel,
				  float *dt)
{
	k_sleep(K_USEC(CEREBRI_CONTROL_PERIOD_US));
	*dt = (float)CEREBRI_CONTROL_PERIOD_US * 1.0e-6f;

	if (!imu_fetch_sync(gyro, accel)) {
		imu_outputs_zero(gyro, accel);
		return false;
	}

	return true;
}

#endif
```

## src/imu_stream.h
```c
#ifndef CEREBRI_IMU_STREAM_H_
#define CEREBRI_IMU_STREAM_H_

#include "topic_flatbuffer.h"

#include <stdbool.h>

int cerebri_imu_stream_init(void);
bool cerebri_imu_stream_wait_next(cerebri_topic_Vec3f_t *gyro,
				  cerebri_topic_Vec3f_t *accel,
				  float *dt);

#endif
```

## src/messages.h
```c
#ifndef D00B381E_08D8_47AC_B779_57B422AF3850
#define D00B381E_08D8_47AC_B779_57B422AF3850

enum actuator_type_t{
    ACTUATOR_TYPE_UNDEFINED = 0,
    ACTUATOR_TYPE_ANGULAR_POSITION,
    ACTUATOR_TYPE_ANGULAR_VELOCITY,
    ACTUATOR_TYPE_LINEAR_POSITION,
    ACTUATOR_TYPE_LINEAR_VELOCITY,
    ACTUATOR_TYPE_FORCE,
    ACTUATOR_TYPE_TORQUE,
    ACTUATOR_TYPE_END
};
struct msg_actuators_t {
    uint64_t uptime_nsec;
    double actuator0_value;
    uint8_t actuator0_type;
    double actuator1_value;
    uint8_t actuator1_type;
    double actuator2_value;
    uint8_t actuator2_type;
    double actuator3_value;
    uint8_t actuator3_type;
    double actuator4_value;
    uint8_t actuator4_type;
    double actuator5_value;
    uint8_t actuator5_type;
    double actuator6_value;
    uint8_t actuator6_type;
    double actuator7_value;
    uint8_t actuator7_type;
};

struct msg_accelerometer_t {
    uint64_t uptime_nsec;
    double x;
    double y;
    double z;
};

struct msg_gyroscope_t {
    uint64_t uptime_nsec;
    double x;
    double y;
    double z;
};

struct msg_magnetometer_t {
    uint64_t uptime_nsec;
    double x;
    double y;
    double z;
};

struct msg_altimeter_t {
    uint64_t uptime_nsec;
    double position;
    double reference;
    double velocity;
};

struct msg_navsat_t {
    uint64_t uptime_nsec;
    double latitude_deg;
    double longitude_deg;
    double altitude;
    double velocity_east;
    double velocity_north;
    double velocity_up;
};

struct msg_waypoint_t {
    uint64_t uptime_nsec;
    double position_x;
    double position_y;
    double position_z;
    double orientation_yaw;
    double velocity_x;
    double velocity_y;
    double velocity_z;
};

struct msg_rc_input_t {
    uint64_t uptime_nsec;
    double roll;
    double pitch;
    double yaw;
    double thrust;
    bool armed;
};

#endif /* D00B381E_08D8_47AC_B779_57B422AF3850 */
```
